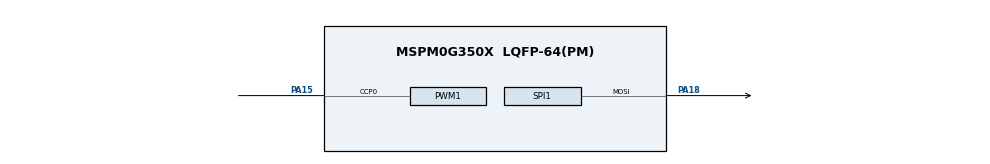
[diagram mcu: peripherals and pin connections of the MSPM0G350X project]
/**
 * @cliArgs --device "MSPM0G350X" --part "Default" --package "LQFP-64(PM)" --product "mspm0_sdk@2.04.00.06"
 * @versions {"tool":"1.22.0+3893"}
 */

/**
 * Import the modules used in this configuration.
 */
const PWM  = scripting.addModule("/ti/driverlib/PWM", {}, false);
const PWM1 = PWM.addInstance();
const SPI  = scripting.addModule("/ti/driverlib/SPI", {}, false);
const SPI1 = SPI.addInstance();

/**
 * Write custom configuration values to the imported modules.
 */
PWM1.$name                      = "PWM_0";
PWM1.ccIndex                    = [0];
PWM1.timerCount                 = 8000;
PWM1.peripheral.ccp0Pin.$assign = "PA15";
PWM1.PWM_CHANNEL_0.$name        = "ti_driverlib_pwm_PWMTimerCC0";
PWM1.PWM_CHANNEL_0.dutyCycle    = 50;
PWM1.ccp0PinConfig.$name        = "ti_driverlib_gpio_GPIOPinGeneric2";

const Board = scripting.addModule("/ti/driverlib/Board", {}, false);

SPI1.rxFifoThreshold                    = "DL_SPI_RX_FIFO_LEVEL_ONE_FRAME";
SPI1.frameFormat                        = "MOTO3";
SPI1.polarity                           = "1";
SPI1.phase                              = "1";
SPI1.enabledInterrupts                  = ["TX"];
SPI1.txFifoThreshold                    = "DL_SPI_TX_FIFO_LEVEL_EMPTY";
SPI1.direction                          = "PICO";
SPI1.targetBitRate                      = 2500000;
SPI1.$name                              = "SPI_1";
SPI1.peripheral.$assign                 = "SPI1";
SPI1.peripheral.mosiPin.$assign         = "PA18";
SPI1.sclkPinConfig.direction            = scripting.forceWrite("OUTPUT");
SPI1.sclkPinConfig.onlyInternalResistor = scripting.forceWrite(false);
SPI1.sclkPinConfig.passedPeripheralType = scripting.forceWrite("Digital");
SPI1.sclkPinConfig.$name                = "ti_driverlib_gpio_GPIOPinGeneric0";
SPI1.mosiPinConfig.direction            = scripting.forceWrite("OUTPUT");
SPI1.mosiPinConfig.hideOutputInversion  = scripting.forceWrite(false);
SPI1.mosiPinConfig.onlyInternalResistor = scripting.forceWrite(false);
SPI1.mosiPinConfig.passedPeripheralType = scripting.forceWrite("Digital");
SPI1.mosiPinConfig.$name                = "ti_driverlib_gpio_GPIOPinGeneric1";

const SYSCTL                 = scripting.addModule("/ti/driverlib/SYSCTL", {}, false);
SYSCTL.forceDefaultClkConfig = true;
SYSCTL.clockTreeEn           = true;

/**
 * Pinmux solution for unlocked pins/peripherals. This ensures that minor changes to the automatic solver in a future
 * version of the tool will not impact the pinmux you originally saw.  These lines can be completely deleted in order to
 * re-solve from scratch.
 */
PWM1.peripheral.$suggestSolution           = "TIMA1";
Board.peripheral.$suggestSolution          = "DEBUGSS";
Board.peripheral.swclkPin.$suggestSolution = "PA20";
Board.peripheral.swdioPin.$suggestSolution = "PA19";
SPI1.peripheral.sclkPin.$suggestSolution   = "PA17";
